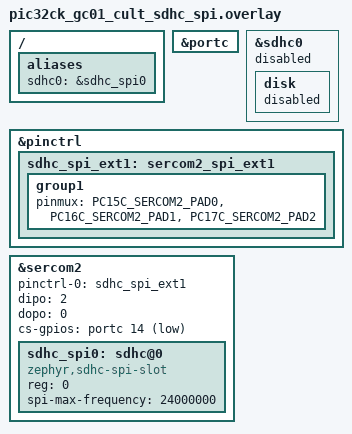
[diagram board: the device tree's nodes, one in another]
/*
 * SPDX-FileCopyrightText: Copyright (c) 2026 Microchip Technology Inc.
 * SPDX-License-Identifier: Apache-2.0
 */

/*
 * SD Card SPI Mode Configuration for PIC32CK GC01 Curiosity Ultra
 * Uses IO1 Xplained Pro on EXT1 header
 */

/ {
	aliases {
		sdhc0 = &sdhc_spi0;
	};
};

&portc {
	status = "okay";
};

&sdhc0 {
	status = "disabled";

	disk {
		status = "disabled";
	};
};

&pinctrl {
	sdhc_spi_ext1: sercom2_spi_ext1 {
		group1 {
			pinmux = <PC15C_SERCOM2_PAD0>,
				 <PC16C_SERCOM2_PAD1>,
				 <PC17C_SERCOM2_PAD2>;
		};
	};
};

&sercom2 {
	status = "okay";
	pinctrl-0 = <&sdhc_spi_ext1>;
	pinctrl-names = "default";
	dipo = <2>;
	dopo = <0>;
	cs-gpios = <&portc 14 GPIO_ACTIVE_LOW>;

	sdhc_spi0: sdhc@0 {
		compatible = "zephyr,sdhc-spi-slot";
		reg = <0>;
		status = "okay";
		spi-max-frequency = <24000000>;
	};
};
